# XMC4200 register map
Vendor: Infineon; File version: 1.5.3 (Reference Manual v1.5)
CPU: CM4 r2p0, little endian, MPU, FPU, 6 interrupt priority bits
Registers are 32-bit, read-write, reset 0x0 unless marked. A register's access mark holds for its fields unless they carry their own. Offsets are from the block's base; [hi:lo] are bit positions; 'fields as' and 'values as' point back to an identical list.

## USB0 — Universal Serial Bus
Base 0x50040000
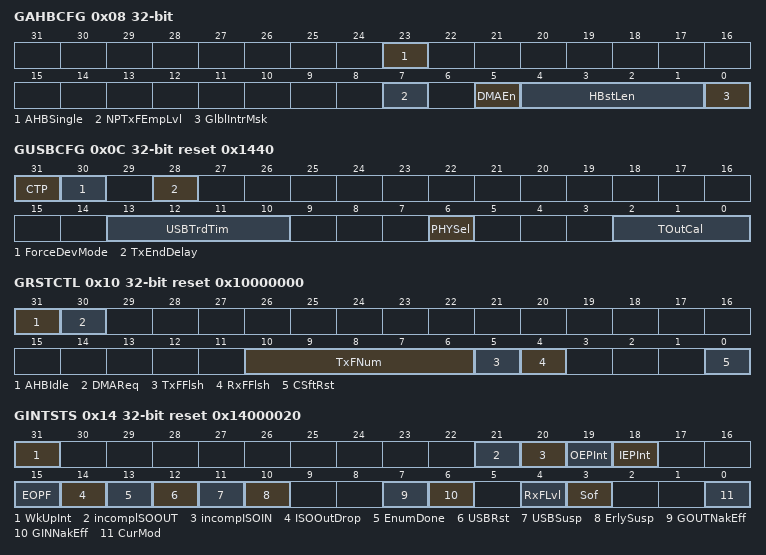
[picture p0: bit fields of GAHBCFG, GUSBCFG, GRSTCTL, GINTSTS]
0x08 GAHBCFG — AHB Configuration Register
  [23] AHBSingle — AHB Single Support
    0=The remaining data in a transfer is sent using INCR burst size. This is the default mode.; 1=The remaining data in a transfer is sent using single burst size
  [7] NPTxFEmpLvl — Non-Periodic TxFIFO Empty Level
    0=DIEPINTx.TxFEmp interrupt indicates that the IN Endpoint TxFIFO is half empty; 1=DIEPINTx.TxFEmp interrupt indicates that the IN Endpoint TxFIFO is completely empty
  [5] DMAEn — DMA Enable
    0=Core operates in Slave mode; 1=Core operates in a DMA mode
  [4:1] HBstLen — Burst Length/Type
    0=Single; 1=INCR; 3=INCR4; 5=INCR8; 7=INCR16
  [0] GlblIntrMsk — Global Interrupt Mask
    0=Mask the interrupt assertion to the application; 1=Unmask the interrupt assertion to the application
0x0C GUSBCFG access per field reset 0x1440 — USB Configuration Register
  [31] CTP rw — Corrupt Tx packet
  [30] ForceDevMode rw — Force Device Mode
    0=Normal Mode; 1=Force Device Mode
  [28] TxEndDelay rw
    0=Normal mode; 1=Introduce Tx end delay timers
  [13:10] USBTrdTim rw — USB Turnaround Time
  [6] PHYSel ro — USB 1.1 Full-Speed Serial Transceiver Select
    1=USB 1.1 full-speed serial transceiver
  [2:0] TOutCal rw — FS Timeout Calibration
0x10 GRSTCTL access per field reset 0x10000000 — Reset Register
  [31] AHBIdle ro — AHB Master Idle
  [30] DMAReq ro — DMA Request Signal
  [10:6] TxFNum rw — TxFIFO Number
    0=Tx FIFO 0 flush in device mode; 1=Tx FIFO 1 flush in device mode; 2=Tx FIFO 2 flush in device mode; 15=Tx FIFO 15 flush in device mode; 16=Flush all the transmit FIFOs in device or host mode
  [5] TxFFlsh rw — TxFIFO Flush
  [4] RxFFlsh rw — RxFIFO Flush
  [0] CSftRst rw — Core Soft Reset
0x14 GINTSTS access per field reset 0x14000020 — Interrupt Register
  [31] WkUpInt rw — Resume/Remote Wakeup Detected Interrupt
  [21] incomplSOOUT rw — Incomplete Isochronous OUT Transfer
  [20] incompISOIN rw — Incomplete Isochronous IN Transfer
  [19] OEPInt ro — OUT Endpoints Interrupt
  [18] IEPInt ro — IN Endpoints Interrupt
  [15] EOPF rw — End of Periodic Frame Interrupt
  [14] ISOOutDrop rw — Isochronous OUT Packet Dropped Interrupt
  [13] EnumDone rw — Enumeration Done
  [12] USBRst rw — USB Reset
  [11] USBSusp rw — USB Suspend
  [10] ErlySusp rw — Early Suspend
  [7] GOUTNakEff ro — Global OUT NAK Effective
  [6] GINNakEff ro — Global IN Non-Periodic NAK Effective
  [4] RxFLvl ro — RxFIFO Non-Empty
  [3] Sof rw — Start of Frame
  [0] CurMod ro — Current Mode of Operation
    0=Device mode
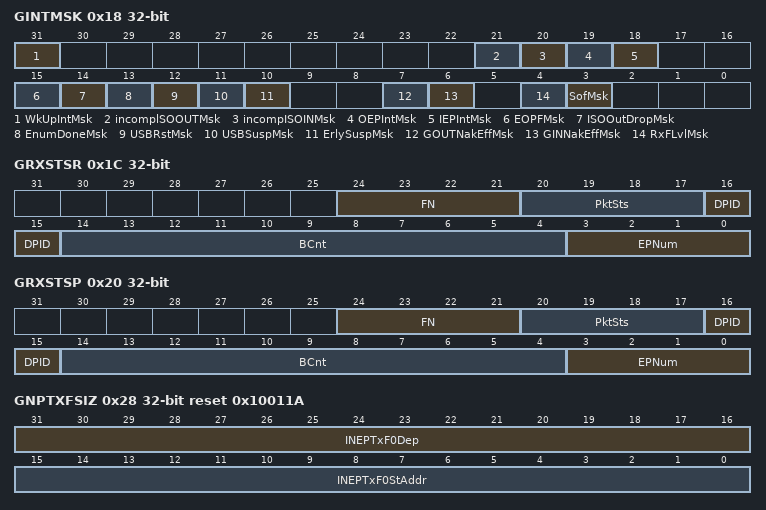
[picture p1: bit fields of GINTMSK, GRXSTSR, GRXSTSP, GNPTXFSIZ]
0x18 GINTMSK — Interrupt Mask Register
  [31] WkUpIntMsk — Resume/Remote Wakeup Detected Interrupt Mask
  [21] incomplSOOUTMsk — Incomplete Isochronous OUT Transfer Mask
  [20] incompISOINMsk — Incomplete Isochronous IN Transfer Mask
  [19] OEPIntMsk — OUT Endpoints Interrupt Mask
  [18] IEPIntMsk — IN Endpoints Interrupt Mask
  [15] EOPFMsk — End of Periodic Frame Interrupt Mask
  [14] ISOOutDropMsk — Isochronous OUT Packet Dropped Interrupt Mask
  [13] EnumDoneMsk — Enumeration Done Mask
  [12] USBRstMsk — USB Reset Mask
  [11] USBSuspMsk — USB Suspend Mask
  [10] ErlySuspMsk — Early Suspend Mask
  [7] GOUTNakEffMsk — Global OUT NAK Effective Mask
  [6] GINNakEffMsk — Global Non-periodic IN NAK Effective Mask
  [4] RxFLvlMsk — Receive FIFO Non-Empty Mask
  [3] SofMsk — Start of Frame Mask
0x1C GRXSTSR ro — Receive Status Debug Read Register
  [24:21] FN — Frame Number
  [20:17] PktSts — Packet Status
    1=Global OUT NAK (triggers an interrupt); 2=OUT data packet received; 3=OUT transfer completed (triggers an interrupt); 4=SETUP transaction completed (triggers an interrupt); 6=SETUP data packet received
  [16:15] DPID — Data PID
    0=DATA0; 2=DATA1; 1=DATA2; 3=MDATA
  [14:4] BCnt — Byte Count
  [3:0] EPNum — Endpoint Number
0x20 GRXSTSP ro read-has-side-effects — Receive Status Read and Pop Register
  fields as GRXSTSR
0x24 GRXFSIZ reset 0x11A — Receive FIFO Size Register
  [15:0] RxFDep — RxFIFO Depth
0x28 GNPTXFSIZ reset 0x10011A — Non-Periodic Transmit FIFO Size Register
  [31:16] INEPTxF0Dep — IN Endpoint TxFIFO 0 Depth
  [15:0] INEPTxF0StAddr — IN Endpoint FIFO0 Transmit RAM Start Address
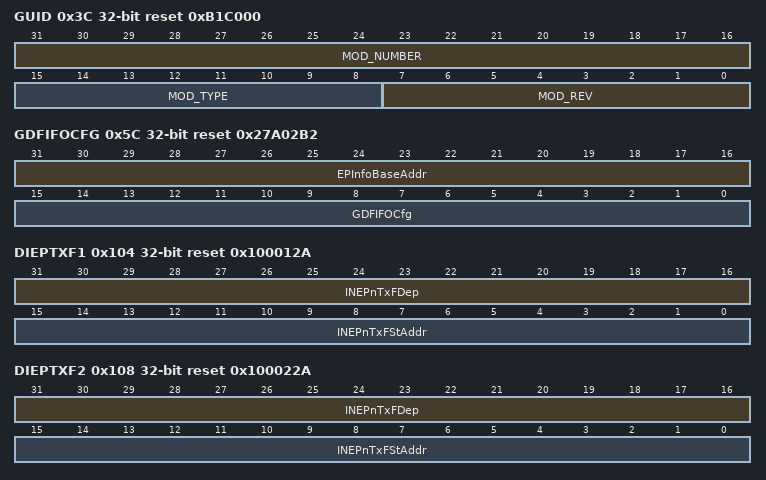
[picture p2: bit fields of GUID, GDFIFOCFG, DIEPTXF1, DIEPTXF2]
0x3C GUID reset 0xB1C000 (reset mask 0xFFFFFF00) — USB Module Identification Register
  [31:16] MOD_NUMBER — Module Number
  [15:8] MOD_TYPE — Module Type
  [7:0] MOD_REV — Module Revision
0x5C GDFIFOCFG reset 0x27A02B2 — Global DFIFO Software Config Register
  [31:16] EPInfoBaseAddr, [15:0] GDFIFOCfg
0x104 DIEPTXF1 reset 0x100012A — Device IN Endpoint 1 Transmit FIFO Size Register
  [31:16] INEPnTxFDep — IN Endpoint TxFIFO Depth
  [15:0] INEPnTxFStAddr — IN Endpoint FIFOn Transmit RAM Start Address
0x108 DIEPTXF2 reset 0x100022A — Device IN Endpoint 2 Transmit FIFO Size Register
  fields as DIEPTXF1
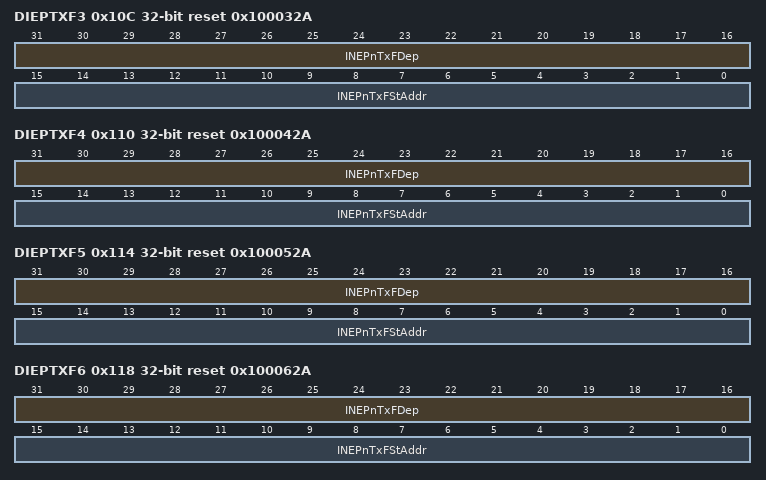
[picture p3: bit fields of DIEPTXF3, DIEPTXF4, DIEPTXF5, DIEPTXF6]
0x10C DIEPTXF3 reset 0x100032A — Device IN Endpoint 3 Transmit FIFO Size Register
  fields as DIEPTXF1
0x110 DIEPTXF4 reset 0x100042A — Device IN Endpoint 4 Transmit FIFO Size Register
  fields as DIEPTXF1
0x114 DIEPTXF5 reset 0x100052A — Device IN Endpoint 5 Transmit FIFO Size Register
  fields as DIEPTXF1
0x118 DIEPTXF6 reset 0x100062A — Device IN Endpoint 6 Transmit FIFO Size Register
  fields as DIEPTXF1
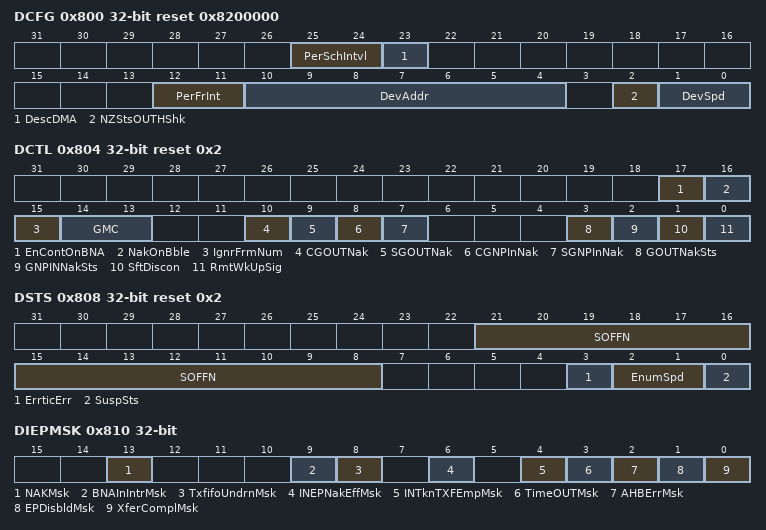
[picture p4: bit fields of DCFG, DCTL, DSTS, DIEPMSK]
0x800 DCFG reset 0x8200000 — Device Configuration Register
  [25:24] PerSchIntvl — Periodic Scheduling Interval
    0=25% of frame; 1=50% of frame; 2=75% of frame
  [23] DescDMA — Enable Scatter/Gather DMA in Device mode.
  [12:11] PerFrInt — Periodic Frame Interval
    0=80% of the frame interval; 1=85%; 2=90%; 3=95%
  [10:4] DevAddr — Device Address
  [2] NZStsOUTHShk — Non-Zero-Length Status OUT Handshake
    1=Send a STALL handshake on a nonzero-length status OUT transaction and do not send the received OUT packet to the application; 0=Send the received OUT packet to the application (zero-length or nonzero-length) and send a handshake based on the NAK and STALL bits for the endpoint in the Device Endpoint Control register
  [1:0] DevSpd — Device Speed
    3=Full speed (USB 1.1 transceiver clock is 48 MHz)
0x804 DCTL access per field reset 0x2 — Device Control Register
  [17] EnContOnBNA rw — Enable continue on BNA
    0=After receiving BNA interrupt, the core disables the endpoint. When the endpoint is re-enabled by the application, the core starts processing from the DOEPDMA descriptor.; 1=After receiving BNA interrupt, the core disables the endpoint. When the endpoint is re-enabled by the application, the core starts processing from the descriptor that received the BNA interrupt.
  [16] NakOnBble rw — Set NAK automatically on babble
  [15] IgnrFrmNum rw — Ignore frame number for isochronous endpoints in case of Scatter/Gather DMA
    0=Scatter/Gather enabled: The core transmits the packets only in the frame number in which they are intended to be transmitted. Scatter/Gather disabled: Periodic transfer interrupt feature is disabled; the application must program transfers for periodic endpoints every frame; 1=Scatter/Gather enabled: The core ignores the frame number, sending packets immediately as the packets are ready. Scatter/Gather disabled: Periodic transfer interrupt feature is enabled; the application can program transfers for multiple frames for periodic endpoints.
  [14:13] GMC rw — Global Multi Count
    0=Invalid; 1=1 packet; 2=2 packets; 3=3 packets
  [10] CGOUTNak wo — Clear Global OUT NAK
  [9] SGOUTNak wo — Set Global OUT NAK
  [8] CGNPInNak wo — Clear Global Non-periodic IN NAK
  [7] SGNPInNak wo — Set Global Non-periodic IN NAK
  [3] GOUTNakSts ro — Global OUT NAK Status
    0=A handshake is sent based on the FIFO Status and the NAK and STALL bit settings; 1=No data is written to the RxFIFO, irrespective of space availability. Sends a NAK handshake on all packets, except on SETUP transactions. All isochronous OUT packets are dropped.
  [2] GNPINNakSts ro — Global Non-periodic IN NAK Status
    0=A handshake is sent out based on the data availability in the transmit FIFO; 1=A NAK handshake is sent out on all non-periodic IN endpoints, irrespective of the data availability in the transmit FIFO
  [1] SftDiscon rw — Soft Disconnect
    0=Normal operation. When this bit is cleared after a soft disconnect, the core drives a device connect event to the USB host. When the device is reconnected, the USB host restarts device enumeration.; 1=The core drives a device disconnect event to the USB host
  [0] RmtWkUpSig rw — Remote Wakeup Signaling
0x808 DSTS ro reset 0x2 — Device Status Register
  [21:8] SOFFN — Frame Number of the Received SOF
  [3] ErrticErr — Erratic Error
  [2:1] EnumSpd — Enumerated Speed
    3=Full speed (PHY clock is running at 48 MHz)
  [0] SuspSts — Suspend Status
0x810 DIEPMSK — Device IN Endpoint Common Interrupt Mask Register
  [13] NAKMsk — NAK interrupt Mask
  [9] BNAInIntrMsk — BNA Interrupt Mask
  [8] TxfifoUndrnMsk — Fifo Underrun Mask
  [6] INEPNakEffMsk — IN Endpoint NAK Effective Mask
  [4] INTknTXFEmpMsk — IN Token Received When TxFIFO Empty Mask
  [3] TimeOUTMsk — Timeout Condition Mask
  [2] AHBErrMsk — AHB Error Mask
  [1] EPDisbldMsk — Endpoint Disabled Interrupt Mask
  [0] XferComplMsk — Transfer Completed Interrupt Mask
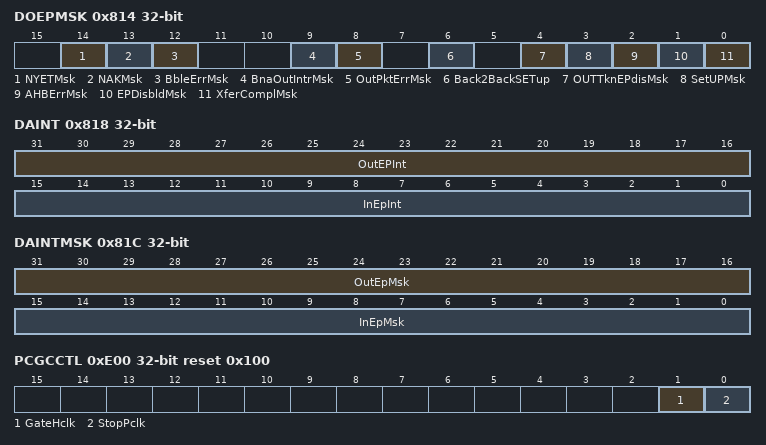
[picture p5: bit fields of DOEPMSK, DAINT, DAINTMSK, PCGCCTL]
0x814 DOEPMSK — Device OUT Endpoint Common Interrupt Mask Register
  [14] NYETMsk — NYET Interrupt Mask
  [13] NAKMsk — NAK Interrupt Mask
  [12] BbleErrMsk — Babble Interrupt Mask
  [9] BnaOutIntrMsk — BNA interrupt Mask
  [8] OutPktErrMsk — OUT Packet Error Mask
  [6] Back2BackSETup — Back-to-Back SETUP Packets Received Mask
  [4] OUTTknEPdisMsk — OUT Token Received when Endpoint Disabled Mask
  [3] SetUPMsk — SETUP Phase Done Mask
  [2] AHBErrMsk — AHB Error
  [1] EPDisbldMsk — Endpoint Disabled Interrupt Mask
  [0] XferComplMsk — Transfer Completed Interrupt Mask
0x818 DAINT ro — Device All Endpoints Interrupt Register
  [31:16] OutEPInt — OUT Endpoint Interrupt Bits
  [15:0] InEpInt — IN Endpoint Interrupt Bits
0x81C DAINTMSK — Device All Endpoints Interrupt Mask Register
  [31:16] OutEpMsk — OUT EP Interrupt Mask Bits
  [15:0] InEpMsk — IN EP Interrupt Mask Bits
0x828 DVBUSDIS reset 0x17D7 — Device VBUS Discharge Time Register
  [15:0] DVBUSDis — Device Vbus Discharge Time
0x82C DVBUSPULSE reset 0x5B8 — Device VBUS Pulsing Time Register
  [11:0] DVBUSPulse — Device Vbus Pulsing Time
0x834 DIEPEMPMSK — Device IN Endpoint FIFO Empty Interrupt Mask Register
  [15:0] InEpTxfEmpMsk — IN EP Tx FIFO Empty Interrupt Mask Bits
0xE00 PCGCCTL reset 0x100 — Power and Clock Gating Control Register
  [1] GateHclk, [0] StopPclk

## Notices in the file
Copyright (C) 2016 Infineon Technologies AG. All rights reserved.
Infineon Technologies AG (Infineon) is supplying this software for use with
Infineon's microcontrollers.  This file can be freely distributed within
development tools that are supporting such microcontrollers.
THIS SOFTWARE IS PROVIDED "AS IS".  NO WARRANTIES, WHETHER EXPRESS, IMPLIED
OR STATUTORY, INCLUDING, BUT NOT LIMITED TO, IMPLIED WARRANTIES OF
MERCHANTABILITY AND FITNESS FOR A PARTICULAR PURPOSE APPLY TO THIS SOFTWARE.
INFINEON SHALL NOT, IN ANY CIRCUMSTANCES, BE LIABLE FOR SPECIAL, INCIDENTAL,
OR CONSEQUENTIAL DAMAGES, FOR ANY REASON WHATSOEVER.
